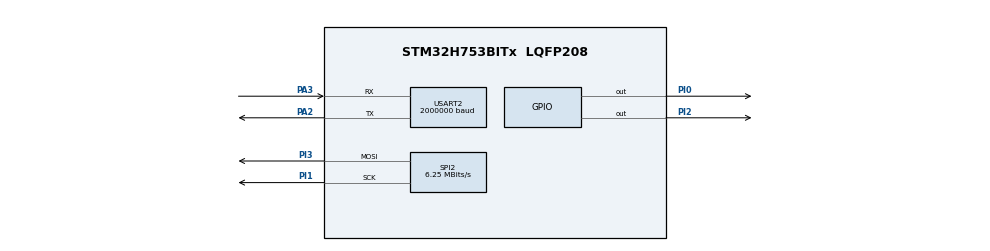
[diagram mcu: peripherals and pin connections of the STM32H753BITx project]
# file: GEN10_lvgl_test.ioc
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CORTEX_M7.CPU_DCache=Disabled
CORTEX_M7.CPU_ICache=Disabled
Dma.Request0=SPI2_TX
Dma.Request1=USART2_TX
Dma.SPI2_TX.0.Direction=DMA_MEMORY_TO_PERIPH
Dma.SPI2_TX.0.EventEnable=DISABLE
Dma.SPI2_TX.0.FIFOMode=DMA_FIFOMODE_DISABLE
Dma.SPI2_TX.0.Instance=DMA1_Stream3
Dma.SPI2_TX.0.MemDataAlignment=DMA_MDATAALIGN_BYTE
Dma.SPI2_TX.0.MemInc=DMA_MINC_ENABLE
Dma.SPI2_TX.0.Mode=DMA_NORMAL
Dma.SPI2_TX.0.PeriphDataAlignment=DMA_PDATAALIGN_BYTE
Dma.SPI2_TX.0.PeriphInc=DMA_PINC_DISABLE
Dma.SPI2_TX.0.Polarity=HAL_DMAMUX_REQ_GEN_RISING
Dma.SPI2_TX.0.Priority=DMA_PRIORITY_LOW
Dma.SPI2_TX.0.RequestNumber=1
Dma.SPI2_TX.0.SignalID=NONE
Dma.SPI2_TX.0.SyncEnable=DISABLE
Dma.SPI2_TX.0.SyncPolarity=HAL_DMAMUX_SYNC_NO_EVENT
Dma.SPI2_TX.0.SyncRequestNumber=1
Dma.SPI2_TX.0.SyncSignalID=NONE
Dma.USART2_TX.1.Direction=DMA_MEMORY_TO_PERIPH
Dma.USART2_TX.1.EventEnable=DISABLE
Dma.USART2_TX.1.FIFOMode=DMA_FIFOMODE_DISABLE
Dma.USART2_TX.1.Instance=DMA1_Stream0
Dma.USART2_TX.1.MemDataAlignment=DMA_MDATAALIGN_BYTE
Dma.USART2_TX.1.MemInc=DMA_MINC_ENABLE
Dma.USART2_TX.1.Mode=DMA_NORMAL
Dma.USART2_TX.1.PeriphDataAlignment=DMA_PDATAALIGN_BYTE
Dma.USART2_TX.1.PeriphInc=DMA_PINC_DISABLE
Dma.USART2_TX.1.Polarity=HAL_DMAMUX_REQ_GEN_RISING
Dma.USART2_TX.1.Priority=DMA_PRIORITY_LOW
Dma.USART2_TX.1.RequestNumber=1
Dma.USART2_TX.1.SignalID=NONE
Dma.USART2_TX.1.SyncEnable=DISABLE
Dma.USART2_TX.1.SyncPolarity=HAL_DMAMUX_SYNC_NO_EVENT
Dma.USART2_TX.1.SyncRequestNumber=1
Dma.USART2_TX.1.SyncSignalID=NONE
FREERTOS.MEMORY_ALLOCATION=0
FREERTOS.Tasks01=defaultTask,0,256,StartDefaultTask,Default,NULL,Dynamic,NULL,NULL
FREERTOS.configENABLE_BACKWARD_COMPATIBILITY=0
FREERTOS.configMINIMAL_STACK_SIZE=256
FREERTOS.configTIMER_QUEUE_LENGTH=16
FREERTOS.configTIMER_TASK_PRIORITY=5
FREERTOS.configTIMER_TASK_STACK_DEPTH=512
FREERTOS.configTOTAL_HEAP_SIZE=400000
FREERTOS.configUSE_TIMERS=1
Mcu.Family=STM32H7
Mcu.Name=STM32H753BITx
Mcu.Package=LQFP208
NVIC.DMA1_Stream0_IRQn=true\:5\:0\:false\:false\:true\:true\:false\:true
NVIC.DMA1_Stream3_IRQn=true\:5\:0\:false\:false\:true\:true\:false\:true
NVIC.PriorityGroup=NVIC_PRIORITYGROUP_4
NVIC.SPI2_IRQn=true\:5\:0\:false\:false\:true\:true\:true\:true
NVIC.TIM6_DAC_IRQn=true\:0\:0\:false\:false\:true\:false\:false\:true
NVIC.TimeBase=TIM6_DAC_IRQn
NVIC.TimeBaseIP=TIM6
NVIC.USART2_IRQn=true\:5\:0\:false\:false\:true\:true\:true\:true
PA11.Signal=UART4_RX
PA12.Signal=UART4_TX
PA13\ (JTMS/SWDIO).Mode=Serial_Wire
PA13\ (JTMS/SWDIO).Signal=DEBUG_JTMS-SWDIO
PA14\ (JTCK/SWCLK).Mode=Serial_Wire
PA14\ (JTCK/SWCLK).Signal=DEBUG_JTCK-SWCLK
PA15\ (JTDI).Signal=SPI6_NSS
PA2.Mode=Asynchronous
PA2.Signal=USART2_TX
PA3.Mode=Asynchronous
PA3.Signal=USART2_RX
PB6.Signal=FDCAN2_TX
PD7.Signal=SPI1_MOSI
PD9.Signal=USART3_RX
PF7.Signal=QUADSPI_BK1_IO2
PG10.Signal=SPI1_NSS
PG12.Signal=SPI6_MISO
PG14.Signal=SPI6_MOSI
PG9.Signal=SPI1_MISO
PH0-OSC_IN\ (PH0).Mode=HSE-External-Oscillator
PH0-OSC_IN\ (PH0).Signal=RCC_OSC_IN
PH1-OSC_OUT\ (PH1).Mode=HSE-External-Oscillator
PH1-OSC_OUT\ (PH1).Signal=RCC_OSC_OUT
PH14.GPIO_Speed=GPIO_SPEED_FREQ_HIGH
PH14.Signal=FDCAN1_RX
PH6.Signal=S_TIM12_CH1
PH9.Signal=S_TIM12_CH2
PI0.GPIO_Speed=GPIO_SPEED_FREQ_VERY_HIGH
PI0.PinState=GPIO_PIN_SET
PI0.Signal=GPIO_Output
PI1.GPIO_Speed=GPIO_SPEED_FREQ_MEDIUM
PI1.Mode=TX_Only_Simplex_Unidirect_Master
PI1.Signal=SPI2_SCK
PI2.GPIO_Speed=GPIO_SPEED_FREQ_VERY_HIGH
PI2.PinState=GPIO_PIN_SET
PI2.Signal=GPIO_Output
PI3.GPIO_Speed=GPIO_SPEED_FREQ_MEDIUM
PI3.Mode=TX_Only_Simplex_Unidirect_Master
PI3.Signal=SPI2_MOSI
PI6.Signal=S_TIM8_CH2
PJ10.Signal=SPI5_MOSI
PJ11.Signal=SPI5_MISO
PK0.Signal=SPI5_SCK
PK1.Signal=SPI5_NSS
PK2.Signal=LTDC_G7
ProjectManager.HeapSize=0x800
ProjectManager.StackSize=0x400
ProjectManager.TargetToolchain=STM32CubeIDE
RCC.ADCCLockSelection=RCC_ADCCLKSOURCE_PLL3
RCC.ADCFreq_Value=32000000
RCC.APB1Freq_Value=100000000
RCC.APB2Freq_Value=100000000
RCC.APB3Freq_Value=100000000
RCC.APB4Freq_Value=100000000
RCC.CKPERSourceSelection=RCC_CLKPSOURCE_HSE
RCC.CortexFreq_Value=400000000
RCC.D1PPRE=RCC_APB3_DIV2
RCC.D2PPRE1=RCC_APB1_DIV2
RCC.D2PPRE2=RCC_APB2_DIV2
RCC.D3PPRE=RCC_APB4_DIV2
RCC.DIVM1=2
RCC.DIVM2=2
RCC.DIVM3=4
RCC.DIVN1=50
RCC.DIVN2=20
RCC.DIVN3=32
RCC.DIVQ1=4
RCC.DIVQ3=128
RCC.DIVR3=8
RCC.HCLKFreq_Value=200000000
RCC.HPRE=RCC_HCLK_DIV2
RCC.HRTIMCLockSelection=RCC_HRTIM1CLK_CPUCLK
RCC.HSE_VALUE=32000000
RCC.PLL2FRACN=0
RCC.PLLFRACN=0
RCC.PLLSourceVirtual=RCC_PLLSOURCE_HSE
RCC.PWR_Regulator_Voltage_Scale=PWR_REGULATOR_VOLTAGE_SCALE0
RCC.QSPICLockSelection=RCC_QSPICLKSOURCE_PLL2
RCC.RCC_MCO1Source=RCC_MCO1SOURCE_PLL1QCLK
RCC.SDMMC1CLockSelection=RCC_SDMMCCLKSOURCE_PLL2
RCC.SYSCLKFreq_VALUE=400000000
RCC.SYSCLKSource=RCC_SYSCLKSOURCE_PLLCLK
RCC.Spi45ClockSelection=RCC_SPI45CLKSOURCE_HSI
RCC.USBCLockSelection=RCC_USBCLKSOURCE_HSI48
RCC.USBFreq_Value=48000000
SH.S_TIM12_CH1.0=TIM12_CH1
SH.S_TIM12_CH2.0=TIM12_CH2
SH.S_TIM8_CH2.0=TIM8_CH2
SPI2.BaudRatePrescaler=SPI_BAUDRATEPRESCALER_32
SPI2.CalculateBaudRate=6.25 MBits/s
SPI2.DataSize=SPI_DATASIZE_8BIT
SPI2.Direction=SPI_DIRECTION_2LINES_TXONLY
SPI2.Mode=SPI_MODE_MASTER
SPI2.NSSPolarity=SPI_NSS_POLARITY_HIGH
SPI2.VirtualType=VM_MASTER
USART2.BaudRate=2000000
USART2.VirtualMode-Asynchronous=VM_ASYNC
VP_FREERTOS_VS_CMSIS_V1.Mode=CMSIS_V1
VP_SYS_VS_tim6.Mode=TIM6
board=custom

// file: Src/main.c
/* USER CODE BEGIN Header */
/**
  ******************************************************************************
  * @file           : main.c
  * @brief          : Main program body
  ******************************************************************************
  * @attention
  *
  * <h2><center>&copy; Copyright (c) 2019 STMicroelectronics.
  * All rights reserved.</center></h2>
  *
  * This software component is licensed by ST under BSD 3-Clause license,
  * the "License"; You may not use this file except in compliance with the
  * License. You may obtain a copy of the License at:
  *                        opensource.org/licenses/BSD-3-Clause
  *
  ******************************************************************************
  */
/* USER CODE END Header */

#include "main.h"
#include "cmsis_os.h"

/* USER CODE BEGIN Includes */
#include "disp_renderer.h"
/* USER CODE END Includes */

SPI_HandleTypeDef hspi2;
DMA_HandleTypeDef hdma_spi2_tx;

UART_HandleTypeDef huart2;
DMA_HandleTypeDef hdma_usart2_tx;

osThreadId defaultTaskHandle;

void SystemClock_Config(void);
static void MX_GPIO_Init(void);
static void MX_DMA_Init(void);
static void MX_SPI2_Init(void);
static void MX_USART2_UART_Init(void);
void StartDefaultTask(void const * argument);

int main(void)
{

  /* MCU Configuration--------------------------------------------------------*/

  /* Reset of all peripherals, Initializes the Flash interface and the Systick. */
  HAL_Init();

  /* Configure the system clock */
  SystemClock_Config();

  /* Initialize all configured peripherals */
  MX_GPIO_Init();
  MX_DMA_Init();
  MX_SPI2_Init();
  MX_USART2_UART_Init();

  /* USER CODE BEGIN RTOS_QUEUES */
  /* add queues, ... */
#if 0
  /* USER CODE END RTOS_QUEUES */

  /* Create the thread(s) */
  /* definition and creation of defaultTask */
  osThreadDef(defaultTask, StartDefaultTask, osPriorityNormal, 0, 256);
  defaultTaskHandle = osThreadCreate(osThread(defaultTask), NULL);

  /* USER CODE BEGIN RTOS_THREADS */
#endif
  /* add threads, ... */
  xTaskCreate(displayTask, "displayTask", 2048, NULL, 0, NULL);
  /* USER CODE END RTOS_THREADS */

  /* Start scheduler */
  osKernelStart();

  /* We should never get here as control is now taken by the scheduler */

  /* Infinite loop */
  while (1)
  {

  }
}

void SystemClock_Config(void)
{
  RCC_OscInitTypeDef RCC_OscInitStruct = {0};
  RCC_ClkInitTypeDef RCC_ClkInitStruct = {0};
  RCC_PeriphCLKInitTypeDef PeriphClkInitStruct = {0};

  /** Supply configuration update enable
  */
  HAL_PWREx_ConfigSupply(PWR_LDO_SUPPLY);
  /** Configure the main internal regulator output voltage
  */
  __HAL_PWR_VOLTAGESCALING_CONFIG(PWR_REGULATOR_VOLTAGE_SCALE0);

  while(!__HAL_PWR_GET_FLAG(PWR_FLAG_VOSRDY)) {}
  /** Initializes the CPU, AHB and APB busses clocks
  */
  RCC_OscInitStruct.OscillatorType = RCC_OSCILLATORTYPE_HSE;
  RCC_OscInitStruct.HSEState = RCC_HSE_ON;
  RCC_OscInitStruct.PLL.PLLState = RCC_PLL_ON;
  RCC_OscInitStruct.PLL.PLLSource = RCC_PLLSOURCE_HSE;
  RCC_OscInitStruct.PLL.PLLM = 2;
  RCC_OscInitStruct.PLL.PLLN = 50;
  RCC_OscInitStruct.PLL.PLLP = 2;
  RCC_OscInitStruct.PLL.PLLQ = 4;
  RCC_OscInitStruct.PLL.PLLR = 2;
  RCC_OscInitStruct.PLL.PLLRGE = RCC_PLL1VCIRANGE_3;
  RCC_OscInitStruct.PLL.PLLVCOSEL = RCC_PLL1VCOWIDE;
  RCC_OscInitStruct.PLL.PLLFRACN = 0;
  if (HAL_RCC_OscConfig(&RCC_OscInitStruct) != HAL_OK)
  {
    Error_Handler();
  }
  /** Initializes the CPU, AHB and APB busses clocks
  */
  RCC_ClkInitStruct.ClockType = RCC_CLOCKTYPE_HCLK|RCC_CLOCKTYPE_SYSCLK
                              |RCC_CLOCKTYPE_PCLK1|RCC_CLOCKTYPE_PCLK2
                              |RCC_CLOCKTYPE_D3PCLK1|RCC_CLOCKTYPE_D1PCLK1;
  RCC_ClkInitStruct.SYSCLKSource = RCC_SYSCLKSOURCE_PLLCLK;
  RCC_ClkInitStruct.SYSCLKDivider = RCC_SYSCLK_DIV1;
  RCC_ClkInitStruct.AHBCLKDivider = RCC_HCLK_DIV2;
  RCC_ClkInitStruct.APB3CLKDivider = RCC_APB3_DIV2;
  RCC_ClkInitStruct.APB1CLKDivider = RCC_APB1_DIV2;
  RCC_ClkInitStruct.APB2CLKDivider = RCC_APB2_DIV2;
  RCC_ClkInitStruct.APB4CLKDivider = RCC_APB4_DIV2;

  if (HAL_RCC_ClockConfig(&RCC_ClkInitStruct, FLASH_LATENCY_2) != HAL_OK)
  {
    Error_Handler();
  }
  PeriphClkInitStruct.PeriphClockSelection = RCC_PERIPHCLK_USART2|RCC_PERIPHCLK_SPI2;
  PeriphClkInitStruct.Spi123ClockSelection = RCC_SPI123CLKSOURCE_PLL;
  PeriphClkInitStruct.Usart234578ClockSelection = RCC_USART234578CLKSOURCE_D2PCLK1;
  if (HAL_RCCEx_PeriphCLKConfig(&PeriphClkInitStruct) != HAL_OK)
  {
    Error_Handler();
  }
}

static void MX_SPI2_Init(void)
{

  /* SPI2 parameter configuration*/
  hspi2.Instance = SPI2;
  hspi2.Init.Mode = SPI_MODE_MASTER;
  hspi2.Init.Direction = SPI_DIRECTION_2LINES_TXONLY;
  hspi2.Init.DataSize = SPI_DATASIZE_8BIT;
  hspi2.Init.CLKPolarity = SPI_POLARITY_LOW;
  hspi2.Init.CLKPhase = SPI_PHASE_1EDGE;
  hspi2.Init.NSS = SPI_NSS_SOFT;
  hspi2.Init.BaudRatePrescaler = SPI_BAUDRATEPRESCALER_32;
  hspi2.Init.FirstBit = SPI_FIRSTBIT_MSB;
  hspi2.Init.TIMode = SPI_TIMODE_DISABLE;
  hspi2.Init.CRCCalculation = SPI_CRCCALCULATION_DISABLE;
  hspi2.Init.CRCPolynomial = 0x0;
  hspi2.Init.NSSPMode = SPI_NSS_PULSE_ENABLE;
  hspi2.Init.NSSPolarity = SPI_NSS_POLARITY_HIGH;
  hspi2.Init.FifoThreshold = SPI_FIFO_THRESHOLD_01DATA;
  hspi2.Init.TxCRCInitializationPattern = SPI_CRC_INITIALIZATION_ALL_ZERO_PATTERN;
  hspi2.Init.RxCRCInitializationPattern = SPI_CRC_INITIALIZATION_ALL_ZERO_PATTERN;
  hspi2.Init.MasterSSIdleness = SPI_MASTER_SS_IDLENESS_00CYCLE;
  hspi2.Init.MasterInterDataIdleness = SPI_MASTER_INTERDATA_IDLENESS_00CYCLE;
  hspi2.Init.MasterReceiverAutoSusp = SPI_MASTER_RX_AUTOSUSP_DISABLE;
  hspi2.Init.MasterKeepIOState = SPI_MASTER_KEEP_IO_STATE_DISABLE;
  hspi2.Init.IOSwap = SPI_IO_SWAP_DISABLE;
  if (HAL_SPI_Init(&hspi2) != HAL_OK)
  {
    Error_Handler();
  }

}

static void MX_USART2_UART_Init(void)
{

  huart2.Instance = USART2;
  huart2.Init.BaudRate = 2000000;
  huart2.Init.WordLength = UART_WORDLENGTH_8B;
  huart2.Init.StopBits = UART_STOPBITS_1;
  huart2.Init.Parity = UART_PARITY_NONE;
  huart2.Init.Mode = UART_MODE_TX_RX;
  huart2.Init.HwFlowCtl = UART_HWCONTROL_NONE;
  huart2.Init.OverSampling = UART_OVERSAMPLING_16;
  huart2.Init.OneBitSampling = UART_ONE_BIT_SAMPLE_DISABLE;
  huart2.Init.ClockPrescaler = UART_PRESCALER_DIV1;
  huart2.AdvancedInit.AdvFeatureInit = UART_ADVFEATURE_NO_INIT;
  if (HAL_UART_Init(&huart2) != HAL_OK)
  {
    Error_Handler();
  }
  if (HAL_UARTEx_SetTxFifoThreshold(&huart2, UART_TXFIFO_THRESHOLD_1_8) != HAL_OK)
  {
    Error_Handler();
  }
  if (HAL_UARTEx_SetRxFifoThreshold(&huart2, UART_RXFIFO_THRESHOLD_1_8) != HAL_OK)
  {
    Error_Handler();
  }
  if (HAL_UARTEx_DisableFifoMode(&huart2) != HAL_OK)
  {
    Error_Handler();
  }

}

static void MX_DMA_Init(void)
{

  /* DMA controller clock enable */
  __HAL_RCC_DMA1_CLK_ENABLE();

  /* DMA interrupt init */
  /* DMA1_Stream0_IRQn interrupt configuration */
  HAL_NVIC_SetPriority(DMA1_Stream0_IRQn, 5, 0);
  HAL_NVIC_EnableIRQ(DMA1_Stream0_IRQn);
  /* DMA1_Stream3_IRQn interrupt configuration */
  HAL_NVIC_SetPriority(DMA1_Stream3_IRQn, 5, 0);
  HAL_NVIC_EnableIRQ(DMA1_Stream3_IRQn);

}

static void MX_GPIO_Init(void)
{
  GPIO_InitTypeDef GPIO_InitStruct = {0};

  /* GPIO Ports Clock Enable */
  __HAL_RCC_GPIOE_CLK_ENABLE();
  __HAL_RCC_GPIOI_CLK_ENABLE();
  __HAL_RCC_GPIOC_CLK_ENABLE();
  __HAL_RCC_GPIOF_CLK_ENABLE();
  __HAL_RCC_GPIOH_CLK_ENABLE();
  __HAL_RCC_GPIOA_CLK_ENABLE();
  __HAL_RCC_GPIOB_CLK_ENABLE();
  __HAL_RCC_GPIOJ_CLK_ENABLE();
  __HAL_RCC_GPIOG_CLK_ENABLE();
  __HAL_RCC_GPIOD_CLK_ENABLE();
  __HAL_RCC_GPIOK_CLK_ENABLE();

  /*Configure GPIO pin Output Level */
  HAL_GPIO_WritePin(GPIOI, GPIO_PIN_0|GPIO_PIN_2, GPIO_PIN_SET);

  /*Configure GPIO pins : PE2 PE3 PE4 PE5
                           PE6 PE7 PE8 PE9
                           PE10 PE11 PE12 PE13
                           PE14 PE15 PE0 PE1 */
  GPIO_InitStruct.Pin = GPIO_PIN_2|GPIO_PIN_3|GPIO_PIN_4|GPIO_PIN_5
                          |GPIO_PIN_6|GPIO_PIN_7|GPIO_PIN_8|GPIO_PIN_9
                          |GPIO_PIN_10|GPIO_PIN_11|GPIO_PIN_12|GPIO_PIN_13
                          |GPIO_PIN_14|GPIO_PIN_15|GPIO_PIN_0|GPIO_PIN_1;
  GPIO_InitStruct.Mode = GPIO_MODE_ANALOG;
  GPIO_InitStruct.Pull = GPIO_NOPULL;
  HAL_GPIO_Init(GPIOE, &GPIO_InitStruct);

  /*Configure GPIO pins : PI8 PI9 PI10 PI11
                           PI12 PI13 PI14 PI15
                           PI4 PI5 PI7 */
  GPIO_InitStruct.Pin = GPIO_PIN_8|GPIO_PIN_9|GPIO_PIN_10|GPIO_PIN_11
                          |GPIO_PIN_12|GPIO_PIN_13|GPIO_PIN_14|GPIO_PIN_15
                          |GPIO_PIN_4|GPIO_PIN_5|GPIO_PIN_7;
  GPIO_InitStruct.Mode = GPIO_MODE_ANALOG;
  GPIO_InitStruct.Pull = GPIO_NOPULL;
  HAL_GPIO_Init(GPIOI, &GPIO_InitStruct);

  /*Configure GPIO pins : PC13 PC14 PC15 PC0
                           PC1 PC2 PC3 PC4
                           PC5 PC6 PC7 PC8
                           PC9 PC10 PC11 PC12 */
  GPIO_InitStruct.Pin = GPIO_PIN_13|GPIO_PIN_14|GPIO_PIN_15|GPIO_PIN_0
                          |GPIO_PIN_1|GPIO_PIN_2|GPIO_PIN_3|GPIO_PIN_4
                          |GPIO_PIN_5|GPIO_PIN_6|GPIO_PIN_7|GPIO_PIN_8
                          |GPIO_PIN_9|GPIO_PIN_10|GPIO_PIN_11|GPIO_PIN_12;
  GPIO_InitStruct.Mode = GPIO_MODE_ANALOG;
  GPIO_InitStruct.Pull = GPIO_NOPULL;
  HAL_GPIO_Init(GPIOC, &GPIO_InitStruct);

  /*Configure GPIO pins : PF0 PF1 PF2 PF3
                           PF4 PF5 PF6 PF8
                           PF9 PF10 PF11 PF12
                           PF13 PF14 PF15 */
  GPIO_InitStruct.Pin = GPIO_PIN_0|GPIO_PIN_1|GPIO_PIN_2|GPIO_PIN_3
                          |GPIO_PIN_4|GPIO_PIN_5|GPIO_PIN_6|GPIO_PIN_8
                          |GPIO_PIN_9|GPIO_PIN_10|GPIO_PIN_11|GPIO_PIN_12
                          |GPIO_PIN_13|GPIO_PIN_14|GPIO_PIN_15;
  GPIO_InitStruct.Mode = GPIO_MODE_ANALOG;
  GPIO_InitStruct.Pull = GPIO_NOPULL;
  HAL_GPIO_Init(GPIOF, &GPIO_InitStruct);

  /*Configure GPIO pin : PF7 */
  GPIO_InitStruct.Pin = GPIO_PIN_7;
  GPIO_InitStruct.Mode = GPIO_MODE_AF_PP;
  GPIO_InitStruct.Pull = GPIO_NOPULL;
  GPIO_InitStruct.Speed = GPIO_SPEED_FREQ_LOW;
  GPIO_InitStruct.Alternate = GPIO_AF9_QUADSPI;
  HAL_GPIO_Init(GPIOF, &GPIO_InitStruct);

  /*Configure GPIO pins : PA0 PA1 PA4 PA5
                           PA6 PA7 PA8 PA9
                           PA10 */
  GPIO_InitStruct.Pin = GPIO_PIN_0|GPIO_PIN_1|GPIO_PIN_4|GPIO_PIN_5
                          |GPIO_PIN_6|GPIO_PIN_7|GPIO_PIN_8|GPIO_PIN_9
                          |GPIO_PIN_10;
  GPIO_InitStruct.Mode = GPIO_MODE_ANALOG;
  GPIO_InitStruct.Pull = GPIO_NOPULL;
  HAL_GPIO_Init(GPIOA, &GPIO_InitStruct);

  /*Configure GPIO pins : PH2 PH3 PH4 PH5
                           PH7 PH8 PH10 PH11
                           PH12 PH13 PH15 */
  GPIO_InitStruct.Pin = GPIO_PIN_2|GPIO_PIN_3|GPIO_PIN_4|GPIO_PIN_5
                          |GPIO_PIN_7|GPIO_PIN_8|GPIO_PIN_10|GPIO_PIN_11
                          |GPIO_PIN_12|GPIO_PIN_13|GPIO_PIN_15;
  GPIO_InitStruct.Mode = GPIO_MODE_ANALOG;
  GPIO_InitStruct.Pull = GPIO_NOPULL;
  HAL_GPIO_Init(GPIOH, &GPIO_InitStruct);

  /*Configure GPIO pins : PB0 PB1 PB2 PB10
                           PB11 PB12 PB13 PB14
                           PB15 PB3 PB4 PB5
                           PB7 PB8 PB9 */
  GPIO_InitStruct.Pin = GPIO_PIN_0|GPIO_PIN_1|GPIO_PIN_2|GPIO_PIN_10
                          |GPIO_PIN_11|GPIO_PIN_12|GPIO_PIN_13|GPIO_PIN_14
                          |GPIO_PIN_15|GPIO_PIN_3|GPIO_PIN_4|GPIO_PIN_5
                          |GPIO_PIN_7|GPIO_PIN_8|GPIO_PIN_9;
  GPIO_InitStruct.Mode = GPIO_MODE_ANALOG;
  GPIO_InitStruct.Pull = GPIO_NOPULL;
  HAL_GPIO_Init(GPIOB, &GPIO_InitStruct);

  /*Configure GPIO pins : PJ0 PJ1 PJ2 PJ3
                           PJ4 PJ5 PJ6 PJ7
                           PJ8 PJ9 PJ12 PJ13
                           PJ14 PJ15 */
  GPIO_InitStruct.Pin = GPIO_PIN_0|GPIO_PIN_1|GPIO_PIN_2|GPIO_PIN_3
                          |GPIO_PIN_4|GPIO_PIN_5|GPIO_PIN_6|GPIO_PIN_7
                          |GPIO_PIN_8|GPIO_PIN_9|GPIO_PIN_12|GPIO_PIN_13
                          |GPIO_PIN_14|GPIO_PIN_15;
  GPIO_InitStruct.Mode = GPIO_MODE_ANALOG;
  GPIO_InitStruct.Pull = GPIO_NOPULL;
  HAL_GPIO_Init(GPIOJ, &GPIO_InitStruct);

  /*Configure GPIO pins : PG0 PG1 PG2 PG3
                           PG4 PG5 PG6 PG7
                           PG8 PG11 PG13 PG15 */
  GPIO_InitStruct.Pin = GPIO_PIN_0|GPIO_PIN_1|GPIO_PIN_2|GPIO_PIN_3
                          |GPIO_PIN_4|GPIO_PIN_5|GPIO_PIN_6|GPIO_PIN_7
                          |GPIO_PIN_8|GPIO_PIN_11|GPIO_PIN_13|GPIO_PIN_15;
  GPIO_InitStruct.Mode = GPIO_MODE_ANALOG;
  GPIO_InitStruct.Pull = GPIO_NOPULL;
  HAL_GPIO_Init(GPIOG, &GPIO_InitStruct);

  /*Configure GPIO pins : PH6 PH9 */
  GPIO_InitStruct.Pin = GPIO_PIN_6|GPIO_PIN_9;
  GPIO_InitStruct.Mode = GPIO_MODE_AF_PP;
  GPIO_InitStruct.Pull = GPIO_NOPULL;
  GPIO_InitStruct.Speed = GPIO_SPEED_FREQ_LOW;
  GPIO_InitStruct.Alternate = GPIO_AF2_TIM12;
  HAL_GPIO_Init(GPIOH, &GPIO_InitStruct);

  /*Configure GPIO pins : PD8 PD10 PD11 PD12
                           PD13 PD14 PD15 PD0
                           PD1 PD2 PD3 PD4
                           PD5 PD6 */
  GPIO_InitStruct.Pin = GPIO_PIN_8|GPIO_PIN_10|GPIO_PIN_11|GPIO_PIN_12
                          |GPIO_PIN_13|GPIO_PIN_14|GPIO_PIN_15|GPIO_PIN_0
                          |GPIO_PIN_1|GPIO_PIN_2|GPIO_PIN_3|GPIO_PIN_4
                          |GPIO_PIN_5|GPIO_PIN_6;
  GPIO_InitStruct.Mode = GPIO_MODE_ANALOG;
  GPIO_InitStruct.Pull = GPIO_NOPULL;
  HAL_GPIO_Init(GPIOD, &GPIO_InitStruct);

  /*Configure GPIO pin : PD9 */
  GPIO_InitStruct.Pin = GPIO_PIN_9;
  GPIO_InitStruct.Mode = GPIO_MODE_AF_PP;
  GPIO_InitStruct.Pull = GPIO_NOPULL;
  GPIO_InitStruct.Speed = GPIO_SPEED_FREQ_LOW;
  GPIO_InitStruct.Alternate = GPIO_AF7_USART3;
  HAL_GPIO_Init(GPIOD, &GPIO_InitStruct);

  /*Configure GPIO pins : PJ10 PJ11 */
  GPIO_InitStruct.Pin = GPIO_PIN_10|GPIO_PIN_11;
  GPIO_InitStruct.Mode = GPIO_MODE_AF_PP;
  GPIO_InitStruct.Pull = GPIO_NOPULL;
  GPIO_InitStruct.Speed = GPIO_SPEED_FREQ_LOW;
  GPIO_InitStruct.Alternate = GPIO_AF5_SPI5;
  HAL_GPIO_Init(GPIOJ, &GPIO_InitStruct);

  /*Configure GPIO pins : PK0 PK1 */
  GPIO_InitStruct.Pin = GPIO_PIN_0|GPIO_PIN_1;
  GPIO_InitStruct.Mode = GPIO_MODE_AF_PP;
  GPIO_InitStruct.Pull = GPIO_NOPULL;
  GPIO_InitStruct.Speed = GPIO_SPEED_FREQ_LOW;
  GPIO_InitStruct.Alternate = GPIO_AF5_SPI5;
  HAL_GPIO_Init(GPIOK, &GPIO_InitStruct);

  /*Configure GPIO pin : PK2 */
  GPIO_InitStruct.Pin = GPIO_PIN_2;
  GPIO_InitStruct.Mode = GPIO_MODE_AF_PP;
  GPIO_InitStruct.Pull = GPIO_NOPULL;
  GPIO_InitStruct.Speed = GPIO_SPEED_FREQ_LOW;
  GPIO_InitStruct.Alternate = GPIO_AF14_LTDC;
  HAL_GPIO_Init(GPIOK, &GPIO_InitStruct);

  /*Configure GPIO pins : PA11 PA12 */
  GPIO_InitStruct.Pin = GPIO_PIN_11|GPIO_PIN_12;
  GPIO_InitStruct.Mode = GPIO_MODE_AF_PP;
  GPIO_InitStruct.Pull = GPIO_NOPULL;
  GPIO_InitStruct.Speed = GPIO_SPEED_FREQ_LOW;
  GPIO_InitStruct.Alternate = GPIO_AF6_UART4;
  HAL_GPIO_Init(GPIOA, &GPIO_InitStruct);

  /*Configure GPIO pin : PH14 */
  GPIO_InitStruct.Pin = GPIO_PIN_14;
  GPIO_InitStruct.Mode = GPIO_MODE_AF_PP;
  GPIO_InitStruct.Pull = GPIO_NOPULL;
  GPIO_InitStruct.Speed = GPIO_SPEED_FREQ_HIGH;
  GPIO_InitStruct.Alternate = GPIO_AF9_FDCAN1;
  HAL_GPIO_Init(GPIOH, &GPIO_InitStruct);

  /*Configure GPIO pins : PI0 PI2 */
  GPIO_InitStruct.Pin = GPIO_PIN_0|GPIO_PIN_2;
  GPIO_InitStruct.Mode = GPIO_MODE_OUTPUT_PP;
  GPIO_InitStruct.Pull = GPIO_NOPULL;
  GPIO_InitStruct.Speed = GPIO_SPEED_FREQ_VERY_HIGH;
  HAL_GPIO_Init(GPIOI, &GPIO_InitStruct);

  /*Configure GPIO pin : PA15 */
  GPIO_InitStruct.Pin = GPIO_PIN_15;
  GPIO_InitStruct.Mode = GPIO_MODE_AF_PP;
  GPIO_InitStruct.Pull = GPIO_NOPULL;
  GPIO_InitStruct.Speed = GPIO_SPEED_FREQ_LOW;
  GPIO_InitStruct.Alternate = GPIO_AF7_SPI6;
  HAL_GPIO_Init(GPIOA, &GPIO_InitStruct);

  /*Configure GPIO pin : PD7 */
  GPIO_InitStruct.Pin = GPIO_PIN_7;
  GPIO_InitStruct.Mode = GPIO_MODE_AF_PP;
  GPIO_InitStruct.Pull = GPIO_NOPULL;
  GPIO_InitStruct.Speed = GPIO_SPEED_FREQ_LOW;
  GPIO_InitStruct.Alternate = GPIO_AF5_SPI1;
  HAL_GPIO_Init(GPIOD, &GPIO_InitStruct);

  /*Configure GPIO pins : PG9 PG10 */
  GPIO_InitStruct.Pin = GPIO_PIN_9|GPIO_PIN_10;
  GPIO_InitStruct.Mode = GPIO_MODE_AF_PP;
  GPIO_InitStruct.Pull = GPIO_NOPULL;
  GPIO_InitStruct.Speed = GPIO_SPEED_FREQ_LOW;
  GPIO_InitStruct.Alternate = GPIO_AF5_SPI1;
  HAL_GPIO_Init(GPIOG, &GPIO_InitStruct);

  /*Configure GPIO pins : PG12 PG14 */
  GPIO_InitStruct.Pin = GPIO_PIN_12|GPIO_PIN_14;
  GPIO_InitStruct.Mode = GPIO_MODE_AF_PP;
  GPIO_InitStruct.Pull = GPIO_NOPULL;
  GPIO_InitStruct.Speed = GPIO_SPEED_FREQ_LOW;
  GPIO_InitStruct.Alternate = GPIO_AF5_SPI6;
  HAL_GPIO_Init(GPIOG, &GPIO_InitStruct);

  /*Configure GPIO pins : PK3 PK4 PK5 PK6
                           PK7 */
  GPIO_InitStruct.Pin = GPIO_PIN_3|GPIO_PIN_4|GPIO_PIN_5|GPIO_PIN_6
                          |GPIO_PIN_7;
  GPIO_InitStruct.Mode = GPIO_MODE_ANALOG;
  GPIO_InitStruct.Pull = GPIO_NOPULL;
  HAL_GPIO_Init(GPIOK, &GPIO_InitStruct);

  /*Configure GPIO pin : PB6 */
  GPIO_InitStruct.Pin = GPIO_PIN_6;
  GPIO_InitStruct.Mode = GPIO_MODE_AF_PP;
  GPIO_InitStruct.Pull = GPIO_NOPULL;
  GPIO_InitStruct.Speed = GPIO_SPEED_FREQ_LOW;
  GPIO_InitStruct.Alternate = GPIO_AF9_FDCAN2;
  HAL_GPIO_Init(GPIOB, &GPIO_InitStruct);

  /*Configure GPIO pin : PI6 */
  GPIO_InitStruct.Pin = GPIO_PIN_6;
  GPIO_InitStruct.Mode = GPIO_MODE_AF_PP;
  GPIO_InitStruct.Pull = GPIO_NOPULL;
  GPIO_InitStruct.Speed = GPIO_SPEED_FREQ_LOW;
  GPIO_InitStruct.Alternate = GPIO_AF3_TIM8;
  HAL_GPIO_Init(GPIOI, &GPIO_InitStruct);

}

void StartDefaultTask(void const * argument)
{

  for(;;)
  {
	osDelay(1);
  }
}

void HAL_TIM_PeriodElapsedCallback(TIM_HandleTypeDef *htim)
{
  if (htim->Instance == TIM6) {
    HAL_IncTick();
  }
}

void Error_Handler(void)
{
}

/************************ (C) COPYRIGHT STMicroelectronics *****END OF FILE****/
